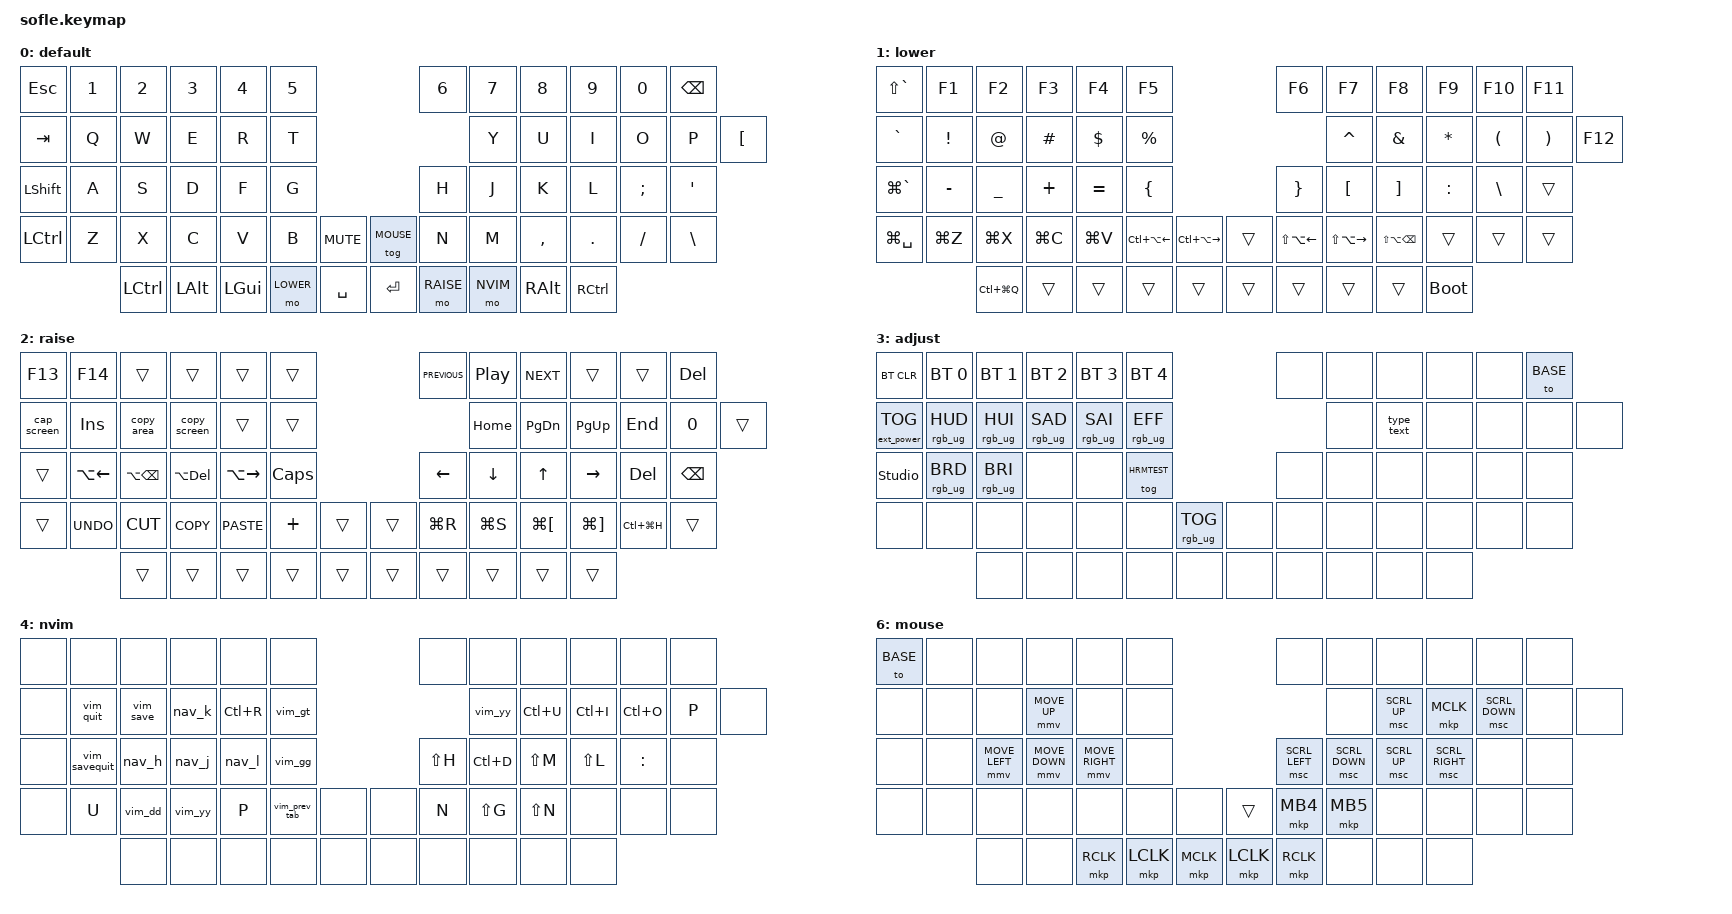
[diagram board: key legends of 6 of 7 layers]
/*
 * Copyright (c) 2020 The ZMK Contributors
 *
 * SPDX-License-Identifier: MIT
 * 
 * Sofle Keyboard ZMK Configuration
 * Features:
 * - Standard QWERTY layout with dedicated layer keys on the thumbs
 * - Layers: LOWER (symbols/numbers), RAISE (navigation/media)
 * - Encoders: Left (Volume), Right (Page Up/Down on base, Brightness on layers)
 * - macOS screenshot shortcuts on RAISE layer
 * - Power management optimizations
 */

#include <behaviors.dtsi>
#include <behaviors/mouse_keys.dtsi>
#include <dt-bindings/zmk/bt.h>
#include <dt-bindings/zmk/ext_power.h>
#include <dt-bindings/zmk/keys.h>
#include <dt-bindings/zmk/rgb.h>
#include <dt-bindings/zmk/pointing.h>

#define BASE    0
#define LOWER   1
#define RAISE   2
#define ADJUST  3
#define NVIM    4
#define HRMTEST 5
#define MOUSE   6

/{
    behaviors {
        /* Home row mods - tuned to prevent misfires during fast typing */
        hm: homerow_mods {
            compatible = "zmk,behavior-hold-tap";
            #binding-cells = <2>;
            tapping-term-ms = <280>;
            quick-tap-ms = <175>;
            require-prior-idle-ms = <150>;
            flavor = "balanced";
            bindings = <&kp>, <&kp>;
        };
    };

    macros {
        /* macOS screenshots */
        cap_screen: cap_screen {
            compatible = "zmk,behavior-macro";
            #binding-cells = <0>;
            bindings = <&kp LG(LS(N3))>;
        };

        copy_screen: copy_screen {
            compatible = "zmk,behavior-macro";
            #binding-cells = <0>;
            bindings = <&kp LC(LS(LG(N3)))>;
        };

        cap_area: cap_area {
            compatible = "zmk,behavior-macro";
            #binding-cells = <0>;
            bindings = <&kp LG(LS(N4))>;
        };

        copy_area: copy_area {
            compatible = "zmk,behavior-macro";
            #binding-cells = <0>;
            bindings = <&kp LC(LS(LG(N4)))>;
        };

        /* nvim window management macros */
        nav_h: nav_h {
            compatible = "zmk,behavior-macro";
            #binding-cells = <0>;
            bindings = <&kp LC(W) &kp H>;
        };
        nav_j: nav_j {
            compatible = "zmk,behavior-macro";
            #binding-cells = <0>;
            bindings = <&kp LC(W) &kp J>;
        };
        nav_k: nav_k {
            compatible = "zmk,behavior-macro";
            #binding-cells = <0>;
            bindings = <&kp LC(W) &kp K>;
        };
        nav_l: nav_l {
            compatible = "zmk,behavior-macro";
            #binding-cells = <0>;
            bindings = <&kp LC(W) &kp L>;
        };

        type_text: type_text {
            compatible = "zmk,behavior-macro";
            #binding-cells = <0>;
            bindings = <&kp Z &kp A &kp Y &kp C &kp E &kp V &kp I &kp E>;
        };

        /* nvim command macros */
        vim_save: vim_save {
            compatible = "zmk,behavior-macro";
            #binding-cells = <0>;
            bindings = <&kp COLON &kp W &kp RET>;
        };
        vim_quit: vim_quit {
            compatible = "zmk,behavior-macro";
            #binding-cells = <0>;
            bindings = <&kp COLON &kp Q &kp RET>;
        };
        vim_savequit: vim_savequit {
            compatible = "zmk,behavior-macro";
            #binding-cells = <0>;
            bindings = <&kp COLON &kp W &kp Q &kp RET>;
        };
        vim_dd: vim_dd {
            compatible = "zmk,behavior-macro";
            #binding-cells = <0>;
            bindings = <&kp D &kp D>;
        };
        vim_yy: vim_yy {
            compatible = "zmk,behavior-macro";
            #binding-cells = <0>;
            bindings = <&kp Y &kp Y>;
        };
        vim_gg: vim_gg {
            compatible = "zmk,behavior-macro";
            #binding-cells = <0>;
            bindings = <&kp G &kp G>;
        };
        vim_gt: vim_gt {
            compatible = "zmk,behavior-macro";
            #binding-cells = <0>;
            bindings = <&kp G &kp T>;
        };
        vim_prev_tab: vim_prev_tab {
            compatible = "zmk,behavior-macro";
            #binding-cells = <0>;
            bindings = <&kp G &kp LS(T)>;
        };
    };
    
    // Activate ADJUST layer by pressing raise and lower
    conditional_layers {
        compatible = "zmk,conditional-layers";

        adjust_layer {
            if-layers = <LOWER RAISE>;
            then-layer = <ADJUST>;
        };
    };

    keymap {
        compatible = "zmk,keymap";

        default_layer {
            display-name = "default";
            // ┌───────┬───────┬───────┬───────┬───────┬───────┐                         ┌───────┬───────┬───────┬───────┬───────┬───────┐
            // │  ESC  │   1   │   2   │   3   │   4   │   5   │                         │   6   │   7   │   8   │   9   │   0   │ BKSPC │
            // ├───────┼───────┼───────┼───────┼───────┼───────┤                         ├───────┼───────┼───────┼───────┼───────┼───────┤
            // │  TAB  │   Q   │   W   │   E   │   R   │   T   │                         │   Y   │   U   │   I   │   O   │   P   │   [   │
            // ├───────┼───────┼───────┼───────┼───────┼───────┤                         ├───────┼───────┼───────┼───────┼───────┼───────┤
            // │ SHIFT │   A   │   S   │   D   │   F   │   G   │                         │   H   │   J   │   K   │   L   │   ;   │   '   │
            // ├───────┼───────┼───────┼───────┼───────┼───────┼───────┐         ┌───────┼───────┼───────┼───────┼───────┼───────┼───────┤
            // │ LCTRL │   Z   │   X   │   C   │   V   │   B   │ MUTE  │         │ NONE  │   N   │   M   │   ,   │   .   │   /   │   \   │
            // └───────┴───────┼───────┼───────┼───────┼───────┼───────┤         ├───────┼───────┼───────┼───────┼───────┴───────┴───────┘
            //                 │ LCTRL │ LALT  │ LGUI  │LOWER  │ SPACE │         │ ENTER │ RAISE │ RGUI  │ RALT  │ RCTRL │
            //                 └───────┴───────┴───────┴───────┴───────┘         └───────┴───────┴───────┴───────┴───────┘
            bindings = <
&kp ESCAPE        &kp N1        &kp N2              &kp N3            &kp N4          &kp N5                            &kp N6          &kp N7            &kp N8             &kp N9           &kp N0           &kp BSPC
&kp TAB           &kp Q         &kp W               &kp E             &kp R           &kp T                             &kp Y           &kp U             &kp I              &kp O            &kp P            &kp LEFT_BRACKET
&kp LSHFT         &kp A         &kp S               &kp D             &kp F           &kp G                             &kp H           &kp J             &kp K              &kp L            &kp SEMI          &kp SQT
&kp LCTRL         &kp Z         &kp X               &kp C             &kp V           &kp B      &kp C_MUTE    &tog MOUSE  &kp N           &kp M             &kp COMMA          &kp DOT          &kp FSLH          &kp BSLH
&kp LCTRL  &kp LALT  &kp LGUI  &mo LOWER  &kp SPACE     &kp RET  &mo RAISE  &mo NVIM  &kp RALT   &kp RCTRL            >;

            sensor-bindings = <&inc_dec_kp C_VOL_UP C_VOL_DN &inc_dec_kp PG_UP PG_DN>;
        };

        lower_layer {
            display-name = "lower";
            // ┌───────┬───────┬───────┬───────┬───────┬───────┐                         ┌───────┬───────┬───────┬───────┬───────┬───────┐
            // │   ~   │  F1   │  F2   │  F3   │  F4   │  F5   │                         │  F6   │  F7   │  F8   │  F9   │  F10  │  F11  │
            // ├───────┼───────┼───────┼───────┼───────┼───────┤                         ├───────┼───────┼───────┼───────┼───────┼───────┤
            // │   `   │   !   │   @   │   #   │   $   │   %   │                         │   ^   │   &   │   *   │   (   │   )   │  F12  │
            // ├───────┼───────┼───────┼───────┼───────┼───────┤                         ├───────┼───────┼───────┼───────┼───────┼───────┤
            // │ G+`   │   -   │   _   │   +   │   =   │   {   │                         │   }   │   [   │   ]   │   :   │   \   │ TRNS  │
            // ├───────┼───────┼───────┼───────┼───────┼───────┼───────┐         ┌───────┼───────┼───────┼───────┼───────┼───────┼───────┤
            // │ G+SPC │  G+Z  │  G+X  │  G+C  │  G+V  │ CA<-  │ CA->  │         │ TRNS  │ SA<-  │ SA->  │ SA-BS │ TRNS  │ TRNS  │ TRNS  │
            // └───────┴───────┼───────┼───────┼───────┼───────┼───────┤         ├───────┼───────┼───────┼───────┴───────┴───────┘───────┘
            //                 │ C+G+Q │ TRNS  │ TRNS  │ TRNS  │ TRNS  │         │ TRNS  │ TRNS  │ TRNS  │ BOOT  │
            //                 └───────┴───────┴───────┴───────┴───────┘         └───────┴───────┴───────┴───────┘
            bindings = <
&kp LS(GRAVE)      &kp F1     &kp F2              &kp F3         &kp F4     &kp F5                       &kp F6     &kp F7    &kp F8     &kp F9     &kp F10   &kp F11
&kp GRAVE          &kp EXCL   &kp AT              &kp HASH       &kp DLLR   &kp PRCNT                    &kp CARET  &kp AMPS  &kp ASTRK  &kp LPAR   &kp RPAR  &kp F12
&kp LG(GRAVE)      &kp MINUS  &kp UNDERSCORE  &kp PLUS       &kp EQUAL  &kp LBRC                     &kp RBRC   &kp LBKT  &kp RBKT   &kp COLON  &kp BSLH  &trans
&kp LG(SPACE)      &kp LG(Z)  &kp LG(X)           &kp LG(C)      &kp LG(V)  &kp LC(LA(LEFT))  &kp LC(LA(RIGHT))  &trans  &kp LS(LA(LEFT))  &kp LS(LA(RIGHT))  &kp LS(LA(BSPC))  &trans  &trans  &trans
                              &kp LC(LG(Q))      &trans         &trans     &trans     &trans    &trans  &trans     &trans    &trans     &bootloader
            >;

            sensor-bindings = <&inc_dec_kp C_VOL_UP C_VOL_DN &inc_dec_kp C_BRIGHTNESS_INC C_BRIGHTNESS_DEC>;
        };

        raise_layer {
            display-name = "raise";
            // ┌───────┬───────┬───────┬───────┬───────┬───────┐                         ┌───────┬───────┬───────┬───────┬───────┬───────┐
            // │  F13  │  F14  │ TRNS  │ TRNS  │ TRNS  │ TRNS  │                         │  PREV │ PLAY  │ NEXT  │ TRNS  │ TRNS  │  DEL  │
            // ├───────┼───────┼───────┼───────┼───────┼───────┤                         ├───────┼───────┼───────┼───────┼───────┼───────┤
            // │ CAPSCR│  INS  │ CPYARE│ CPYSCR│ TRNS  │ TRNS  │                         │ HOME  │ PGDN  │ PGUP  │  END  │   0   │ TRNS  │
            // ├───────┼───────┼───────┼───────┼───────┼───────┤                         ├───────┼───────┼───────┼───────┼───────┼───────┤
            // │ TRNS  │  A<-  │ A-BS  │ A-DEL │  A->  │ CAPS  │                         │ LEFT  │ DOWN  │  UP   │ RIGHT │  DEL  │ BSPC  │
            // ├───────┼───────┼───────┼───────┼───────┼───────┼───────┐         ┌───────┼───────┼───────┼───────┼───────┼───────┼───────┤
            // │ TRNS  │ UNDO  │  CUT  │ COPY  │ PASTE │   +   │ TRNS  │         │ TRNS  │  G+R  │  G+S  │  G+[  │  G+]  │ C+G+H │ TRNS  │
            // └───────┴───────┼───────┼───────┼───────┼───────┼───────┤         ├───────┼───────┼───────┼───────┼───────┴───────┴───────┘
            //                 │ TRNS  │ TRNS  │ TRNS  │ TRNS  │ TRNS  │         │ TRNS  │ TRNS  │ TRNS  │ TRNS  │ TRNS  │
            //                 └───────┴───────┴───────┴───────┴───────┘         └───────┴───────┴───────┴───────┴───────┘
            bindings = <
&kp F13  &kp F14      &trans         &trans           &trans        &trans                          &kp C_PREVIOUS  &kp C_PLAY_PAUSE  &kp C_NEXT  &trans     &trans   &kp DELETE
&cap_screen  &kp INS       &copy_area     &copy_screen      &trans        &trans                          &kp HOME        &kp PG_DN         &kp PG_UP   &kp END    &kp N0   &trans
&trans  &kp LA(LEFT)  &kp LA(BSPC)   &kp LA(DELETE)   &kp LA(RIGHT) &kp CLCK                        &kp LEFT        &kp DOWN          &kp UP      &kp RIGHT  &kp DEL  &kp BSPC
&trans  &kp K_UNDO    &kp K_CUT      &kp K_COPY       &kp K_PASTE   &kp PLUS      &trans &trans  &kp LG(R)        &kp LG(S)         &kp LG(LBKT)      &kp LG(RBKT)     &kp LC(LG(H))      &trans
                      &trans         &trans           &trans        &trans        &trans    &trans  &trans          &trans            &trans      &trans
            >;

            sensor-bindings = <&inc_dec_kp C_VOL_UP C_VOL_DN &inc_dec_kp C_BRIGHTNESS_INC C_BRIGHTNESS_DEC>;
        };

        adjust_layer {
            display-name = "adjust";
            // ┌───────┬───────┬───────┬───────┬───────┬───────┐                         ┌───────┬───────┬───────┬───────┬───────┬───────┐
            // │ BTCLR │  BT1  │  BT2  │  BT3  │  BT4  │  BT5  │                         │ NONE  │ NONE  │ NONE  │ NONE  │ NONE  │ NONE  │
            // ├───────┼───────┼───────┼───────┼───────┼───────┤                         ├───────┼───────┼───────┼───────┼───────┼───────┤
            // │EXTPWR │RGBHUD │RGBHUI │RGBSAD │RGBSAI │RGBEFF │                         │ NONE  │ TEXT  │ NONE  │ NONE  │ NONE  │ NONE  │
            // ├───────┼───────┼───────┼───────┼───────┼───────┤                         ├───────┼───────┼───────┼───────┼───────┼───────┤
            // │UNLOCK │RGBBRD │RGBBRI │ NONE  │ NONE  │TOGHRM │                         │ NONE  │ NONE  │ NONE  │ NONE  │ NONE  │ NONE  │
            // ├───────┼───────┼───────┼───────┼───────┼───────┼───────┐         ┌───────┼───────┼───────┼───────┼───────┼───────┼───────┤
            // │ NONE  │ NONE  │ NONE  │ NONE  │ NONE  │ NONE  │RGBTOG │         │ NONE  │ NONE  │ NONE  │ NONE  │ NONE  │ NONE  │ NONE  │
            // └───────┴───────┼───────┼───────┼───────┼───────┼───────┤         ├───────┼───────┼───────┼───────┼───────┴───────┴───────┘
            //                 │ NONE  │ NONE  │ NONE  │ NONE  │ NONE  │         │ NONE  │ NONE  │ NONE  │ NONE  │ NONE  │
            //                 └───────┴───────┴───────┴───────┴───────┘         └───────┴───────┴───────┴───────┴───────┘
            bindings = <
&bt BT_CLR         &bt BT_SEL 0     &bt BT_SEL 1     &bt BT_SEL 2     &bt BT_SEL 3     &bt BT_SEL 4                               &none  &none  &none  &none  &none  &to BASE
&ext_power EP_TOG  &rgb_ug RGB_HUD  &rgb_ug RGB_HUI  &rgb_ug RGB_SAD  &rgb_ug RGB_SAI  &rgb_ug RGB_EFF                            &none  &type_text  &none  &none  &none  &none
&studio_unlock     &rgb_ug RGB_BRD  &rgb_ug RGB_BRI  &none            &none            &tog HRMTEST                               &none  &none  &none  &none  &none  &none
&none              &none            &none            &none            &none            &none            &rgb_ug RGB_TOG    &none  &none  &none  &none  &none  &none  &none
                                    &none            &none            &none            &none            &none              &none  &none  &none  &none  &none
            >;
        };

        nvim_layer {
            display-name = "nvim";
            // Left: window mgmt + commands | Right: navigation + motions
            // ┌───────┬───────┬───────┬───────┬───────┬───────┐                         ┌───────┬───────┬───────┬───────┬───────┬───────┐
            // │ NONE  │ NONE  │ NONE  │ NONE  │ NONE  │ NONE  │                         │ NONE  │ NONE  │ NONE  │ NONE  │ NONE  │ NONE  │
            // ├───────┼───────┼───────┼───────┼───────┼───────┤                         ├───────┼───────┼───────┼───────┼───────┼───────┤
            // │ NONE  │  :q   │  :w   │ C-W K │ C-R   │  gt   │                         │  yy   │ C-U   │ C-I   │ C-O   │  p    │ NONE  │
            // ├───────┼───────┼───────┼───────┼───────┼───────┤                         ├───────┼───────┼───────┼───────┼───────┼───────┤
            // │ NONE  │  :wq  │ C-W H │ C-W J │ C-W L │  gg   │                         │  S-H  │ C-D   │ S-M   │  S-L  │  :    │ NONE  │
            // ├───────┼───────┼───────┼───────┼───────┼───────┼───────┐         ┌───────┼───────┼───────┼───────┼───────┼───────┼───────┤
            // │ NONE  │  u    │  dd   │  yy   │  p    │  gT   │ NONE  │         │ NONE  │  n    │  S-G  │  S-N  │ NONE  │ NONE  │ NONE  │
            // └───────┴───────┼───────┼───────┼───────┼───────┼───────┤         ├───────┼───────┼───────┼───────┼───────┴───────┴───────┘
            //                 │ NONE  │ NONE  │ NONE  │ NONE  │ NONE  │         │ NONE  │ NONE  │ NONE  │ NONE  │ NONE  │
            //                 └───────┴───────┴───────┴───────┴───────┘         └───────┴───────┴───────┴───────┴───────
            bindings = <
&none          &none        &none        &none        &none        &none                                &none        &none        &none        &none        &none        &none
&none          &vim_quit    &vim_save    &nav_k       &kp LC(R)    &vim_gt                              &vim_yy      &kp LC(U)    &kp LC(I)    &kp LC(O)    &kp P        &none
&none          &vim_savequit &nav_h      &nav_j       &nav_l       &vim_gg                              &kp LS(H)    &kp LC(D)    &kp LS(M)    &kp LS(L)    &kp COLON    &none
&none          &kp U        &vim_dd      &vim_yy      &kp P        &vim_prev_tab      &none        &none      &kp N        &kp LS(G)    &kp LS(N)    &none        &none        &none
                            &none        &none        &none        &none        &none        &none      &none        &none        &none        &none
            >;
        };

        hrmtest_layer {
            display-name = "hrm";
            // Transparent overlay — only overrides home row with hold-tap mods
            // Everything else falls through to BASE (or LOWER/RAISE/ADJUST when active)
            // Toggle on/off via ADJUST layer (LOWER+RAISE+G)
            // Home row: A=GUI S=ALT D=CTRL F=SHIFT | J=SHIFT K=CTRL L=ALT ;=GUI
            bindings = <
&trans         &trans            &trans            &trans             &trans             &trans                               &trans          &trans             &trans              &trans            &trans              &trans
&trans         &trans            &trans            &trans             &trans             &trans                               &trans          &trans             &trans              &trans            &trans              &trans
&trans         &hm LGUI A        &hm LALT S        &hm LCTRL D        &hm LSHFT F        &trans                               &trans          &hm RSHFT J        &hm RCTRL K         &hm RALT L        &hm RGUI SEMI       &trans
&trans         &trans            &trans            &trans             &trans             &trans      &trans        &trans     &trans          &trans             &trans              &trans            &trans              &trans
               &trans  &trans  &trans  &trans     &trans  &trans  &trans  &trans   &trans            >;

            sensor-bindings = <&inc_dec_kp C_VOL_UP C_VOL_DN &inc_dec_kp PG_UP PG_DN>;
        };

        mouse_layer {
            display-name = "mouse";
            // Hold right encoder to enter | Scroll on HJKL, clicks on left hand, cursor move on ESDF
            // ┌───────┬───────┬───────┬───────┬───────┬───────┐                         ┌───────┬───────┬───────┬───────┬───────┬───────┐
            // │toBase │ NONE  │ NONE  │ NONE  │ NONE  │ NONE  │                         │ NONE  │ NONE  │ NONE  │ NONE  │ NONE  │ NONE  │
            // ├───────┼───────┼───────┼───────┼───────┼───────┤                         ├───────┼───────┼───────┼───────┼───────┼───────┤
            // │ NONE  │ NONE  │ NONE  │MV UP  │ NONE  │ NONE  │                         │ NONE  │SCR UP │ MCLK  │SCR DN │ NONE  │ NONE  │
            // ├───────┼───────┼───────┼───────┼───────┼───────┤                         ├───────┼───────┼───────┼───────┼───────┼───────┤
            // │ NONE  │ NONE  │MV LFT │MV DN  │MV RGT │ NONE  │                         │SCR LFT│SCR DN │SCR UP │SCR RGT│ NONE  │ NONE  │
            // ├───────┼───────┼───────┼───────┼───────┼───────┼───────┐         ┌───────┼───────┼───────┼───────┼───────┼───────┼───────┤
            // │ NONE  │ NONE  │ NONE  │ NONE  │ NONE  │ NONE  │ NONE  │         │ TRNS  │  MB4  │  MB5  │ NONE  │ NONE  │ NONE  │ NONE  │
            // └───────┴───────┼───────┼───────┼───────┼───────┼───────┤         ├───────┼───────┼───────┼───────┼───────┴───────┴───────┘
            //                 │ NONE  │ NONE  │ RCLK  │ LCLK  │ MCLK  │         │ LCLK  │ RCLK  │ NONE  │ NONE  │ NONE  │
            //                 └───────┴───────┴───────┴───────┴───────┘         └───────┴───────┴───────┴───────┴───────┘
            bindings = <
&to BASE       &none        &none        &none              &none              &none                                    &none              &none              &none          &none              &none        &none
&none          &none        &none        &mmv MOVE_UP       &none              &none                                    &none              &msc SCRL_UP       &mkp MCLK      &msc SCRL_DOWN     &none        &none
&none          &none        &mmv MOVE_LEFT &mmv MOVE_DOWN   &mmv MOVE_RIGHT    &none                                    &msc SCRL_LEFT     &msc SCRL_DOWN     &msc SCRL_UP   &msc SCRL_RIGHT    &none        &none
&none          &none        &none        &none              &none              &none        &none        &trans          &mkp MB4           &mkp MB5           &none          &none              &none        &none
                            &none        &none              &mkp RCLK          &mkp LCLK    &mkp MCLK    &mkp LCLK       &mkp RCLK          &none              &none          &none
            >;

            sensor-bindings = <&inc_dec_kp C_VOL_UP C_VOL_DN &inc_dec_kp C_VOL_UP C_VOL_DN>;
        };
    };
};
